# STM32H7S register map
File version: 1.0
CPU: CM7 r0p1, little endian, MPU, FPU, 4 interrupt priority bits
Registers are 32-bit, read-write, reset 0x0 unless marked. A register's access mark holds for its fields unless they carry their own. Offsets are from the block's base; [hi:lo] are bit positions; {n}, {i} and the like mark numbered series; 'fields as' and 'values as' point back to an identical list.

## MCE1 — Memory cipher engine
Base 0x5200B800
Same registers: MCE2 0x5200BC00, MCE3 0x5200C000
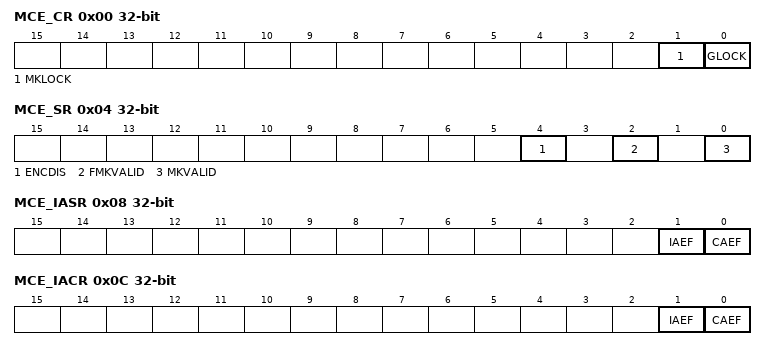
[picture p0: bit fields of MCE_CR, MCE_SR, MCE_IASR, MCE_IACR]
0x00 MCE_CR — MCE configuration register
  [1] MKLOCK — Master keys lock Lock the master key configurations until next reset. This bit is cleared by default and once set it cannot be reset until MCE reset. Effect of this bit depends on the number of master keys. See Section 35.3: MCE implementation for details.
    0=Writes to MCE_MKEYRx and MCE_FMKEYRx registers are allowed; 1=Writes to MCE_MKEYRx and MCE_FMKEYRx registers are ignored until next MCE reset
  [0] GLOCK — Global lock Lock the configuration of most MCE registers until next reset. This bit is cleared by default and once set it cannot be reset until MCE reset.
    0=MCE registers are writable; 1=All writes to MCE registers are ignored, with the exception of MCE_IACR and MCE_IAIER registers
0x04 MCE_SR ro — MCE status register
  [4] ENCDIS — encryption disabled This bit is set by hardware when the encryption feature is not functional. When ENCDIS is set application must reset MCE peripheral to be able to use the encryption feature again.
    0=When ENC bit and BREN are set in MCE_REGCRx all allowed write accesses in region x are encrypted, and all allowed read requests are decrypted; 1=When ENC bit and BREN are set in any MCE_REGCRx all write accesses in region x are ignored, and all read requests return zero. All previously written key material are also erased.
  [2] FMKVALID — Fast master key valid This bit is reserved when fast master key is not present in the MCE instance. See Section 35.3: MCE implementation for detail.
    0=A valid key has not been written in MCE_FMKEYRx registers, or a valid unlocked fast master key has been erased by hardware (if bit was set before); 1=A valid key has been written in MCE_FMKEYRx registers (write R0 -> R1 -> R2 -> R3 or the reverse)
  [0] MKVALID — Master key valid
    0=A valid key has not been written in MCE_MKEYRx registers, or a valid unlocked master key has been erased by hardware (if bit was set before); 1=A valid key has been written in MCE_MKEYRx registers (write R0 -> R1 -> R2 -> R3 or the reverse)
0x08 MCE_IASR ro — MCE illegal access status register
  [1] IAEF — Illegal access error flag This bit is set when an illegal access is detected on the system bus. More details on the error can be found in MCE_IAESR and MCE_IADDR registers. This bit is cleared by setting corresponding bit in MCE_IACR register.
  [0] CAEF — Configuration access error flag This bit is set when an illegal access to any MCE configuration register is detected. Bit is cleared by setting corresponding bit in MCE_IACR register. No additional details on the error is available.
0x0C MCE_IACR wo — MCE illegal access clear register
  [1] IAEF — Illegal access error flag clear Set this bit to clear IAEF bit in MCE_IASR register. Clearing IAEF bit permits to capture new error information in MCE_IAESR and MCE_IADDR registers. Note that clearing this bit does not clear RISAB_IADDR register.
  [0] CAEF — Configuration access error flag clear Set this bit to clear CAEF bit in MCE_IASR register.
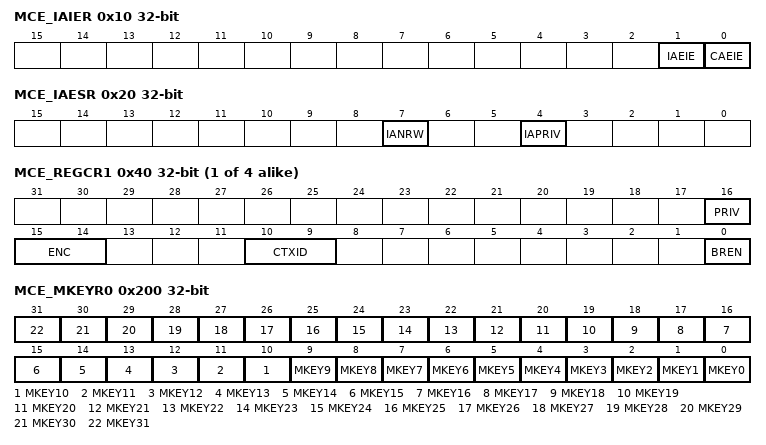
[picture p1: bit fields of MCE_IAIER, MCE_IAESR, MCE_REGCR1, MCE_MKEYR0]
0x10 MCE_IAIER access per field — MCE illegal access interrupt enable register
  [1] IAEIE ro — Illegal access error interrupt enable
    0=Interrupt generation on illegal access errors is disabled; 1=Interrupt generation when an illegal access error occurs (IAEF=1)
  [0] CAEIE rw — Configuration access error interrupt enable
    0=Interrupt generation on configuration access errors is disabled; 1=Interrupt generation when a configuration access error occurs (CAEF=1)
0x1C MCE_PRIVCFGR — MCE privileged configuration register
  [0] PRIV — Privileged configuration
    0=Privileged and unprivileged access are granted to MCE registers; 1=Only privileged access are granted to MCE registers
0x20 MCE_IAESR ro — MCE illegal access error status register
  [7] IANRW — Illegal access read/write When IAEF bit is set in MCE_IASR register IANRW bit captures the access type of the illegal access detected.
    0=Illegal access was a data read or an instruction fetch; 1=Illegal access was a data write
  [4] IAPRIV — Illegal access privilege When IAEF bit is set in MCE_IASR register IAPRIV bit captures the privileged state of the master that issued the illegal access detected on the AXI system bus.
    0=Illegal access was unprivileged; 1=Illegal access was privileged
0x24 MCE_IADDR ro — MCE illegal address register
  [31:0] IADD — Illegal address When IAEF bit is set in MCE_IASR register IADD bitfield captures the 32-bit bus address of the erroneous access. Additional information can be found in MCE_IAESR register.
{0x30+0x10*i} MCE_REGCR{i} (i=1..4) — MCE region {i} configuration register
  [16] PRIV — Privileged region This bit is taken into account only if BREN is set.
    0=Application can access to region x in privileged and unprivileged mode; 1=Application can access to region x in privileged mode only
  [15:14] ENC — Encrypted region Those bits are taken into account only if BREN is set and if the corresponding encryption feature is available in the MCE instance (see Section 35.3: MCE implementation). Write to those bits is ignored if BREN is set.
    0=No effects; 1=Stream cipher - All allowed read (resp. write) requests are decrypted (resp. encrypted) using the stream cipher, when CCEN bit is set in MCE_CCzCFGR (where CTXID=z).; 2=Block cipher - All allowed read (resp. write) requests are decrypted (resp. encrypted) using the SCA resistant block cipher. If CTXID=0 and MKVALID=0 bypass mode is selected instead. If CTXID=z and CCEN bit is cleared in MCE_CCzCFGR bypass mode is also selected.; 3=Fast block cipher - All allowed read (resp. write) requests are decrypted (resp. encrypted) using the fast block cipher. If CTXID=0 and FMKVALID=0 bypass mode is selected instead. If CTXID=z and CCEN bit is cleared in MCE_CCzCFGR bypass mode is also selected.
  [10:9] CTXID — Context ID This bitfield defines the cryptographic context used by the cipher engine assigned to this region. If ENC=00 bitfield CTXID is ignored. If BREN is set write to this bitfield is ignored. If ENC=01 the key stored in MCE_CC1KEYR is used by the stream cipher. The nonce in MCE_CC1NRx registers and the version in MCE_CC1CR register are also used. If ENC=01 the key stored in MCE_CC2KEYR is used by the stream cipher. The nonce in MCE_CC2NRx registers and the version in MCE_CC2CR register are also used.
    0=If ENC=10 (resp. 11) the key stored in MCE_MKEYR (resp. MCE_FMKEYR) registers is used by the block cipher. If ENC=01 bypass mode is selected instead of stream cipher.; 1=If ENC=10 or 11 the key stored in MCE_CC1KEYR is used by the block cipher; 2=If ENC=10 or 11 the key stored in MCE_CC2KEYR is used by the block cipher; 3=FIELD Reserved
  [0] BREN — Base region enable BREN cannot be set if BADDRSTART > BADDREND.
    0=Region x is disabled. Access control of primary region (any-privilege, no encryption) applies to any access between this region start and end addresses.; 1=Region x is enable. Access controls and encryption option defined in this region apply to any access between this region start and end addresses.
{0x34+0x10*i} MCE_SADDR{i} (i=1..4) — MCE start address for region {i} register
  [31:12] BADDSTART — Region address start This bitfield defines the absolute start address of the region x on 4 kBytes boundary (inclusive). BREN cannot be set if BADDRSTART > BADDREND. When MCE determines the region, the first 12 bits (LSB) and the last 4 bits (MSB) in this register are ignored, and when this register is accessed in read the 4 MSB bits and the 12 LSB bits return zeros (reference value in MCE).
{0x38+0x10*i} MCE_EADDR{i} reset 0xFFF (i=1..4) — MCE end address for region {i} register
  [31:12] BADDEND — Region address end This bitfield defines the absolute end address of the region x on 4 kBytes boundary (inclusive). BREN cannot be set if BADDRSTART > BADDREND. When MCE determines the region, the first 12 bits (LSB) and the last 4 bits (MSB) in this register are ignored, and when this register is accessed in read the 4 MSB bits return zeros and the 12 LSB bits return ones (reference value in MCE).
{0x3C+0x10*i} MCE_ATTR{i} (i=1..4) — MCE attribute for region {i} register
  [16] WREN — Write enable This bit is taken into account only if BREN is set.
    0=Writes to region x are ignored. Reads are allowed.; 1=Region x can be read and written. Restrictions linked to PRIV bit in MCE_REGCRx apply.
0x200 MCE_MKEYR0 wo — MCE master key 0
  [n] MKEY{n} (n=0..31) — Master key bit {n} This key is used by the MCE block cipher in normal, SCA resistant mode, if CTXID=0x0 in MCE_REGCR register.
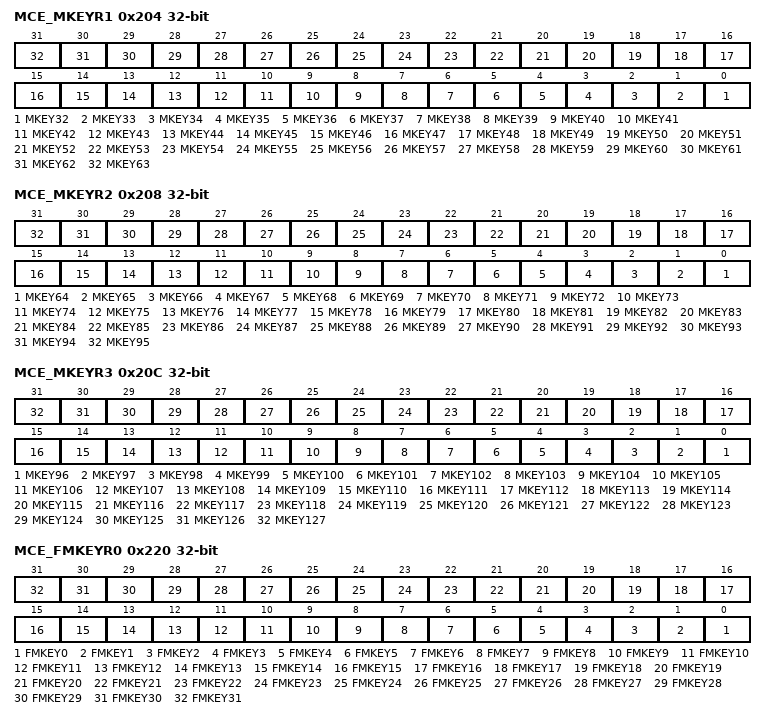
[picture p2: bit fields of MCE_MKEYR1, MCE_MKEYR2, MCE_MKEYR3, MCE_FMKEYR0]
0x204 MCE_MKEYR1 wo — MCE master key 1
  [n-32] MKEY{n} (n=32..63) — Master key bit {n} This key is used by the MCE block cipher in normal, SCA resistant mode, if CTXID=0x0 in MCE_REGCR register.
0x208 MCE_MKEYR2 wo — MCE master key 2
  [n-64] MKEY{n} (n=64..95) — Master key bit {n} This key is used by the MCE block cipher in normal, SCA resistant mode, if CTXID=0x0 in MCE_REGCR register.
0x20C MCE_MKEYR3 wo — MCE master key 3
  [n-96] MKEY{n} (n=96..127) — Master key bit {n} This key is used by the MCE block cipher in normal, SCA resistant mode, if CTXID=0x0 in MCE_REGCR register.
0x220 MCE_FMKEYR0 wo — MCE fast master key 0
  [n] FMKEY{n} (n=0..31) — Fast master key bit {n} This key is used by the MCE block cipher in fast mode, if CTXID=0x0 in MCE_REGCR register.
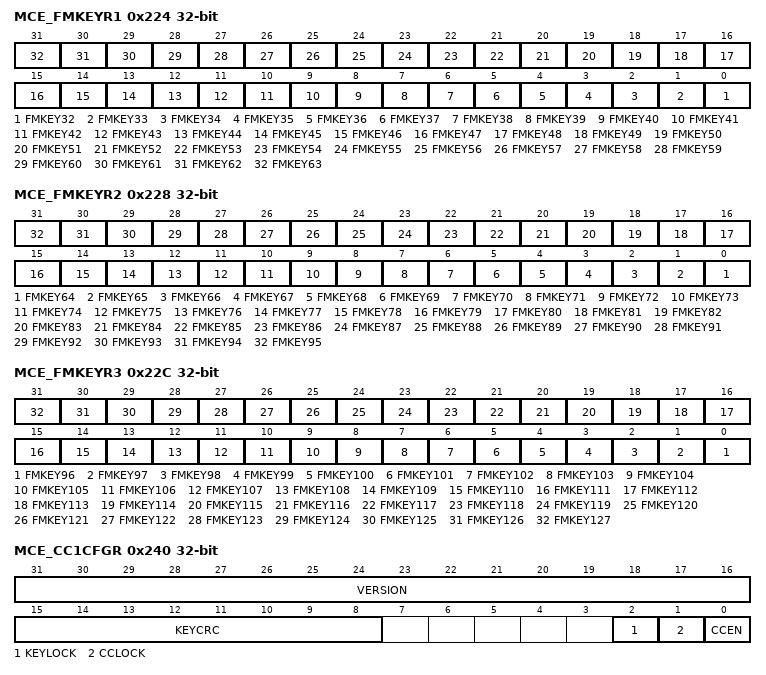
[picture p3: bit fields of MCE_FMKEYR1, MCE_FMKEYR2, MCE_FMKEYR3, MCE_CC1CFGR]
0x224 MCE_FMKEYR1 wo — MCE fast master key 1
  [n-32] FMKEY{n} (n=32..63) — Fast master key bit {n} This key is used by the MCE block cipher in fast mode, if CTXID=0x0 in MCE_REGCR register.
0x228 MCE_FMKEYR2 wo — MCE fast master key 2
  [n-64] FMKEY{n} (n=64..95) — Fast master key bit {n} This key is used by the MCE block cipher in fast mode, if CTXID=0x0 in MCE_REGCR register.
0x22C MCE_FMKEYR3 wo — MCE fast master key 3
  [n-96] FMKEY{n} (n=96..127) — Fast master key bit {n} This key is used by the MCE block cipher in fast mode, if CTXID=0x0 in MCE_REGCR register.
0x240 MCE_CC1CFGR access per field — MCE cipher context 1 configuration register
  [31:16] VERSION rw — Version This 16-bit bitfield must be correctly initialized before CCEN bit is set. Bitfield usage is defined in Section 35.4.6: MCE stream cipher encryption mode.
  [15:8] KEYCRC ro — Key CRC When KEYLOCK=0, KEYCRC information is automatically computed by hardware while loading the key of this region in this exact sequence: KEYR0 then KEYR1 then KEYR2 then finally KEYR3 (all written once). A new KEYCRC computation starts as soon as a new valid sequence is initiated. KEYCRC bitfield reads as zero until a valid sequence is completed (after it return the computed CRC value). When GLOCK=1, KEYCRC bitfield always return the computed CRC value until the next reset. CRC computation is an 8-bit checksum using the standard CRC-8-CCITT algorithm X8 + X2 + X + 1 (according the convention). Note: CRC information is updated, and the key is usable by MCE, only after the last bit of the key has been written. When GLOCK=0 any write to MCE_CCxKEYR registers clears KEYCRC in MCE_CCxCFGR, and makes the cipher context key un-usable (bypass mode is selected instead). To be able to use the key again application must perform this sequence: write to KEYR0 then KEYR1 then KEYR2 then finally KEYR3 (all written once). As KEYLOCK=1 all those writes are ignored, so the correct key is used instead.
  [2] KEYLOCK rw — Key lock Note: This bit is set once. If this bit is set, it can only be cleared to 0 if MCE is reset.
    0=Writes to MCE_CCzKEYR registers are allowed; 1=Writes to MCE_CCzKEYR registers are ignored until next MCE reset
  [1] CCLOCK rw — Cipher context lock Note: This bit is set once. If this bit is set, it can only be cleared to 0 if MCE is reset. Setting this bit forces KEYLOCK bit to 1.
    0=Writes to MCE_CCzCFGR and MCE_CCzNR registers are allowed; 1=Writes to MCE_CCzCFGR and MCE_CCzNR registers are ignored until next MCE reset
  [0] CCEN rw — Cipher context enable
    0=If an enabled region selects CTXID=z bypass mode is selected by MCE; 1=If an enabled region selects CTXID=z with ENC=01 MCE selects with the stream cipher the information stored in MCE_CCzCFGR, MCE_CCzNR and MCE_CCzKEYR. If the enabled region selects ENC=10 or 11 instead MCE selects with the block cipher the key information stored in MCE_CCzKEYR.
0x244 MCE_CC1NR0 — MCE cipher context 1 nonce register 0
  [31:0] SCNONCE — Stream cipher nonce, bits [31:0] This register is used by stream cipher to compute keystream. It must be correctly initialize before CCEN bit is set in MCE_CCzCFGR register. Bitfield usage is defined in Section 35.4.6: MCE stream cipher encryption mode.
0x248 MCE_CC1NR1 — MCE cipher context 1 nonce register 1
  [31:0] SCNONCE — Stream cipher nonce, bits [63:32] Refer to the MCE_CCzNR0 register for description of the SCNONCE[63:0] bitfield.
0x24C MCE_CC1KEYR0 wo — MCE cipher context 1 key register 0
  [31:0] KEY — cipher key, bits [31:0] This register is used by the block or stream cipher of MCE when CTXID = z in encrypted region configuration register. KEY[127:0] must be correctly initialize before CCEN bit is set in MCE_CCzCFGR register.
{0x24C+4i} MCE_CC1KEYR{i} wo (i=1..3) — MCE cipher context 1 key register {i}
  [31:0] KEY — cipher key, bits [{32i+31}:{32i}] Refer to the MCE_CCzKEYR0 register for description of the KEY[127:0] bitfield.
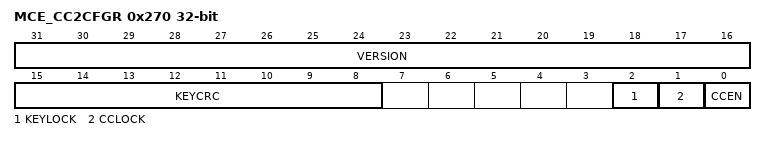
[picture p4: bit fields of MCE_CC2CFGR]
0x270 MCE_CC2CFGR access per field — MCE cipher context 2 configuration register
  fields as MCE_CC1CFGR
0x274 MCE_CC2NR0 — MCE cipher context 2 nonce register 0
  fields as MCE_CC1NR0
0x278 MCE_CC2NR1 — MCE cipher context 2 nonce register 1
  fields as MCE_CC1NR1
0x27C MCE_CC2KEYR0 wo — MCE cipher context 2 key register 0
  fields as MCE_CC1KEYR0
{0x27C+4i} MCE_CC2KEYR{i} wo (i=1..3) — MCE cipher context 2 key register {i}
  fields as MCE_CC1KEYR1
